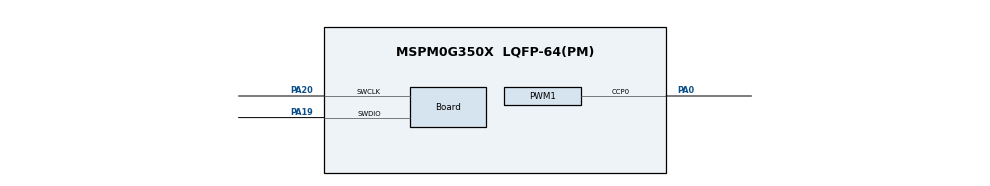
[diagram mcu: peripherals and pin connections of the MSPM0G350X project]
/**
 * @cliArgs --device "MSPM0G350X" --part "Default" --package "LQFP-64(PM)" --product "mspm0_sdk@2.10.00.04"
 * @versions {"tool":"1.27.1+4634"}
 */

/**
 * Import the modules used in this configuration.
 */
const Board         = scripting.addModule("/ti/driverlib/Board");
const PWM           = scripting.addModule("/ti/driverlib/PWM", {}, false);
const PWM1          = PWM.addInstance();
const SYSCTL        = scripting.addModule("/ti/driverlib/SYSCTL");
const ProjectConfig = scripting.addModule("/ti/project_config/ProjectConfig");

/**
 * Write custom configuration values to the imported modules.
 */
const divider7       = system.clockTree["PLL_PDIV"];
divider7.divideValue = 2;

const divider9       = system.clockTree["UDIV"];
divider9.divideValue = 2;

const multiplier2         = system.clockTree["PLL_QDIV"];
multiplier2.multiplyValue = 10;

const mux8       = system.clockTree["HSCLKMUX"];
mux8.inputSelect = "HSCLKMUX_SYSPLL0";

Board.configureUnused             = true;
Board.unusedDirection             = "INPUT";
Board.unusedInternalResistor      = "PULL_UP";
Board.genPeriphPinFile            = true;
Board.genResourceCSV              = true;
Board.peripheral.$assign          = "DEBUGSS";
Board.peripheral.swclkPin.$assign = "PA20";
Board.peripheral.swdioPin.$assign = "PA19";
Board.genFileMod.$name            = "ti_driverlib_BoardPins0";
Board.genFileCSV.$name            = "ti_driverlib_ResourcesCSV0";

PWM1.$name                      = "PWM_0";
PWM1.timerCount                 = 10000;
PWM1.clockPrescale              = 8;
PWM1.timerStartTimer            = true;
PWM1.ccIndex                    = [0];
PWM1.pwmMode                    = "EDGE_ALIGN_UP";
PWM1.PWM_CHANNEL_0.$name        = "ti_driverlib_pwm_PWMTimerCC0";
PWM1.PWM_CHANNEL_0.dutyCycle    = 50;
PWM1.ccp0PinConfig.$name        = "ti_driverlib_gpio_GPIOPinGeneric0";
PWM1.peripheral.$assign         = "TIMA0";
PWM1.peripheral.ccp0Pin.$assign = "PA0";

SYSCTL.clockTreeEn = true;

ProjectConfig.compiler           = "gcc";
ProjectConfig.migrationCondition = true;
